# nrf9230_radiocore register map
Vendor: Nordic Semiconductor; Series: nRF92; File version: 1
CPU: CM33 r0p4, little endian, MPU, FPU, 3 interrupt priority bits, 480 interrupts, 8 SAU regions
Registers are 32-bit, read-write, reset 0x0 unless marked. A register's access mark holds for its fields unless they carry their own. Offsets are from the block's base; [hi:lo] are bit positions; {n}, {i} and the like mark numbered series; 'fields as' and 'values as' point back to an identical list.

## RTC_NS — Real-time counter 0
Base 0x4302B000
Same registers: RTC_S 0x5302B000
0x00 TASKS_START wo — Start RTC counter
  [0] TASKS_START
    1=Trigger task
0x04 TASKS_STOP wo — Stop RTC counter
  [0] TASKS_STOP
    1=Trigger task
0x08 TASKS_CLEAR wo — Clear RTC counter
  [0] TASKS_CLEAR
    1=Trigger task
0x0C TASKS_TRIGOVRFLW wo — Set counter to 0xFFFFF0
  [0] TASKS_TRIGOVRFLW
    1=Trigger task
{0x40+4i} TASKS_CAPTURE[{i}] (i=0..7) wo — Description collection: Capture RTC counter to CC[n] register
  [0] TASKS_CAPTURE — Capture RTC counter to CC[n] register
    1=Trigger task
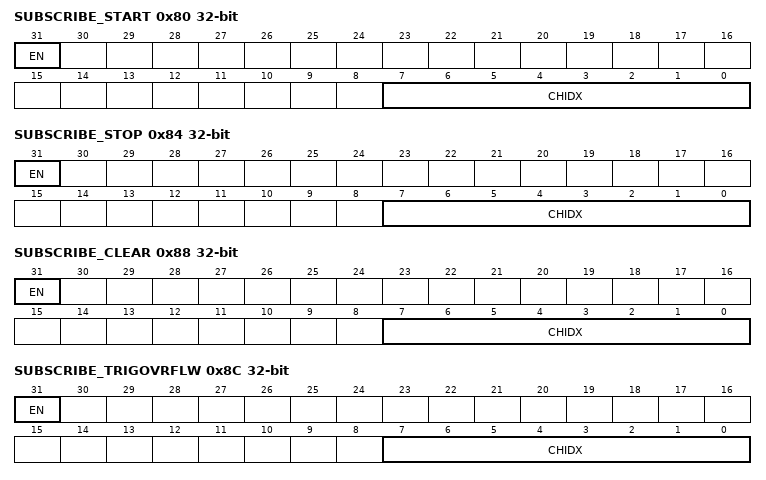
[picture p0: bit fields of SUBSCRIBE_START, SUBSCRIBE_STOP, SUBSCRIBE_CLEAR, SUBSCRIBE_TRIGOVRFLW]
0x80 SUBSCRIBE_START — Subscribe configuration for task START
  [31] EN
    0=Disabled (Disable subscription); 1=Enabled (Enable subscription)
  [7:0] CHIDX — DPPI channel that task START will subscribe to
0x84 SUBSCRIBE_STOP — Subscribe configuration for task STOP
  [31] EN
    values as SUBSCRIBE_START.EN
  [7:0] CHIDX — DPPI channel that task STOP will subscribe to
0x88 SUBSCRIBE_CLEAR — Subscribe configuration for task CLEAR
  [31] EN
    values as SUBSCRIBE_START.EN
  [7:0] CHIDX — DPPI channel that task CLEAR will subscribe to
0x8C SUBSCRIBE_TRIGOVRFLW — Subscribe configuration for task TRIGOVRFLW
  [31] EN
    values as SUBSCRIBE_START.EN
  [7:0] CHIDX — DPPI channel that task TRIGOVRFLW will subscribe to
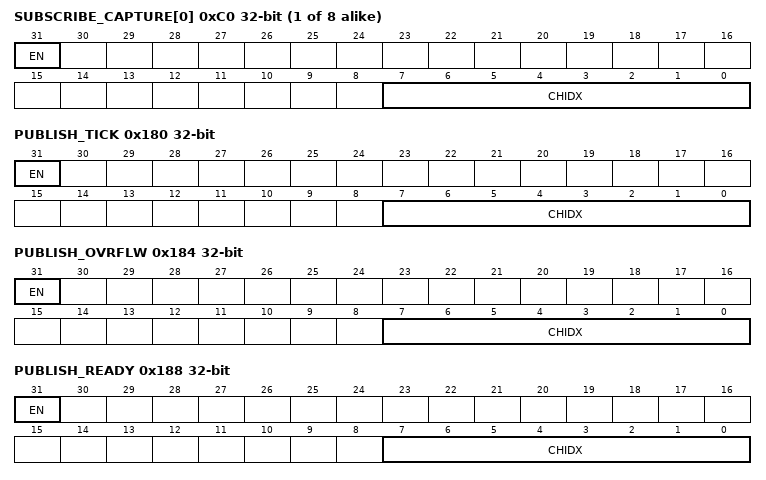
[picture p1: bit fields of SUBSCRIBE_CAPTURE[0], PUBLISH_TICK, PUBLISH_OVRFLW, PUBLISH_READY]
{0xC0+4i} SUBSCRIBE_CAPTURE[{i}] (i=0..7) — Description collection: Subscribe configuration for task CAPTURE[n]
  [31] EN
    values as SUBSCRIBE_START.EN
  [7:0] CHIDX — DPPI channel that task CAPTURE[n] will subscribe to
0x100 EVENTS_TICK — Event on counter increment
  [0] EVENTS_TICK
    0=NotGenerated (Event not generated); 1=Generated (Event generated)
0x104 EVENTS_OVRFLW — Event on counter overflow
  [0] EVENTS_OVRFLW
    values as EVENTS_TICK.EVENTS_TICK
0x108 EVENTS_READY — Event on LFCLK started
  [0] EVENTS_READY
    values as EVENTS_TICK.EVENTS_TICK
{0x140+4i} EVENTS_COMPARE[{i}] (i=0..7) — Description collection: Compare event on CC[n] match
  [0] EVENTS_COMPARE — Compare event on CC[n] match
    values as EVENTS_TICK.EVENTS_TICK
0x180 PUBLISH_TICK — Publish configuration for event TICK
  [31] EN
    0=Disabled (Disable publishing); 1=Enabled (Enable publishing)
  [7:0] CHIDX — DPPI channel that event TICK will publish to
0x184 PUBLISH_OVRFLW — Publish configuration for event OVRFLW
  [31] EN
    values as PUBLISH_TICK.EN
  [7:0] CHIDX — DPPI channel that event OVRFLW will publish to
0x188 PUBLISH_READY — Publish configuration for event READY
  [31] EN
    values as PUBLISH_TICK.EN
  [7:0] CHIDX — DPPI channel that event READY will publish to
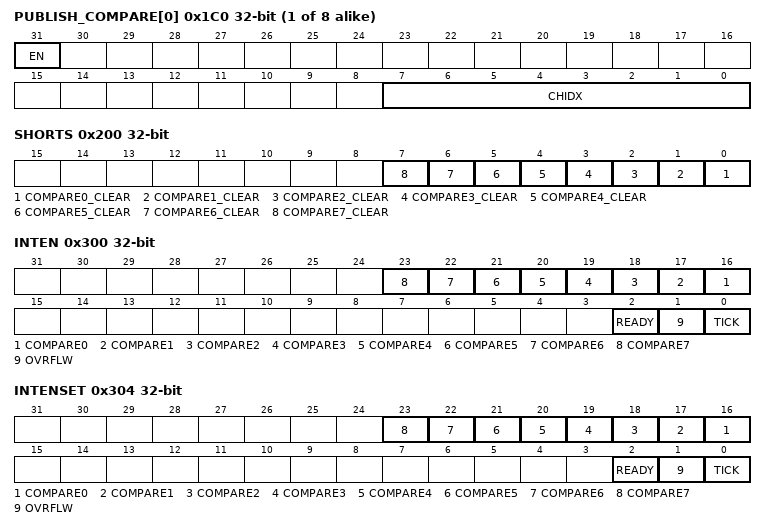
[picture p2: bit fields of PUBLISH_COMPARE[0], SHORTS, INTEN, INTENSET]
{0x1C0+4i} PUBLISH_COMPARE[{i}] (i=0..7) — Description collection: Publish configuration for event COMPARE[n]
  [31] EN
    values as PUBLISH_TICK.EN
  [7:0] CHIDX — DPPI channel that event COMPARE[n] will publish to
0x200 SHORTS — Shortcuts between local events and tasks
  [all] fields
    0=Disabled (Disable shortcut); 1=Enabled (Enable shortcut)
  [n] COMPARE{n}_CLEAR (n=0..7) — Shortcut between event COMPARE[{n}] and task CLEAR
0x300 INTEN — Enable or disable interrupt
  [all] fields
    0=Disabled; 1=Enabled
  [n+16] COMPARE{n} (n=0..7) — Enable or disable interrupt for event COMPARE[{n}]
  [2] READY — Enable or disable interrupt for event READY
  [1] OVRFLW — Enable or disable interrupt for event OVRFLW
  [0] TICK — Enable or disable interrupt for event TICK
0x304 INTENSET — Enable interrupt
  [all] fields
    on read: 0=Disabled (Read: Disabled); 1=Enabled (Read: Enabled) | on write: 1=Set (Enable)
  [n+16] COMPARE{n} (n=0..7) — Write '1' to enable interrupt for event COMPARE[{n}]
  [2] READY — Write '1' to enable interrupt for event READY
  [1] OVRFLW — Write '1' to enable interrupt for event OVRFLW
  [0] TICK — Write '1' to enable interrupt for event TICK
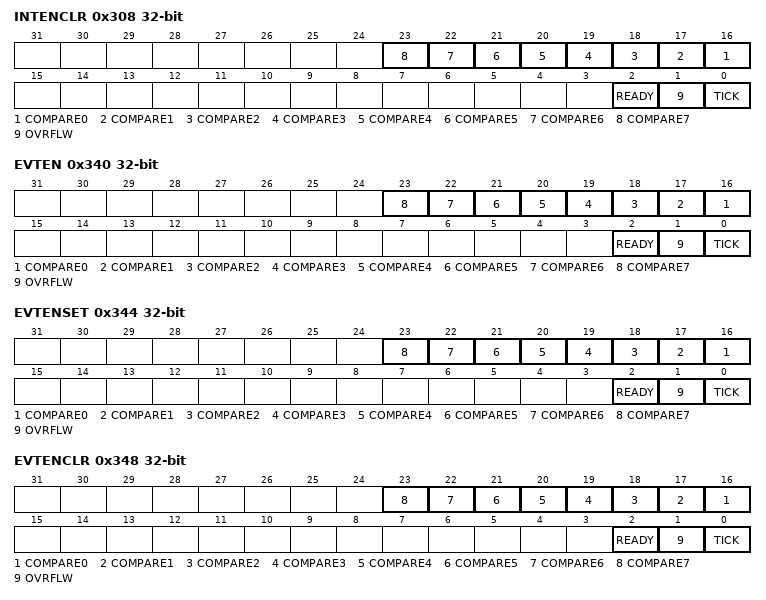
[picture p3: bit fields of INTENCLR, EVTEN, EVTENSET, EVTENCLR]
0x308 INTENCLR — Disable interrupt
  [all] fields
    on read: 0=Disabled (Read: Disabled); 1=Enabled (Read: Enabled) | on write: 1=Clear (Disable)
  [n+16] COMPARE{n} (n=0..7) — Write '1' to disable interrupt for event COMPARE[{n}]
  [2] READY — Write '1' to disable interrupt for event READY
  [1] OVRFLW — Write '1' to disable interrupt for event OVRFLW
  [0] TICK — Write '1' to disable interrupt for event TICK
0x340 EVTEN — Enable or disable event routing
  [all] fields
    0=Disabled; 1=Enabled
  [n+16] COMPARE{n} (n=0..7) — Enable or disable event routing for event COMPARE[{n}]
  [2] READY — Enable or disable event routing for event READY
  [1] OVRFLW — Enable or disable event routing for event OVRFLW
  [0] TICK — Enable or disable event routing for event TICK
0x344 EVTENSET — Enable event routing
  [all] fields
    values as the fields of INTENSET
  [n+16] COMPARE{n} (n=0..7) — Write '1' to enable event routing for event COMPARE[{n}]
  [2] READY — Write '1' to enable event routing for event READY
  [1] OVRFLW — Write '1' to enable event routing for event OVRFLW
  [0] TICK — Write '1' to enable event routing for event TICK
0x348 EVTENCLR — Disable event routing
  [all] fields
    values as the fields of INTENCLR
  [n+16] COMPARE{n} (n=0..7) — Write '1' to disable event routing for event COMPARE[{n}]
  [2] READY — Write '1' to disable event routing for event READY
  [1] OVRFLW — Write '1' to disable event routing for event OVRFLW
  [0] TICK — Write '1' to disable event routing for event TICK
0x400 STATUS ro — Counter status
  [0] COUNTER
    0=Stopped (Counter is stopped); 1=Started (Counter is started and LFCLK is available)
0x500 ENABLE — Clock enable
  [0] LFCLK — Request LFCLK
    0=Disable request LFCLK; 1=Enable request LFCLK
0x504 COUNTER ro — Current counter value
  [23:0] COUNTER — Counter value
0x508 PRESCALER — 12-bit prescaler for counter frequency (32768 / (PRESCALER + 1)). Must be written when RTC is stopped.
  [11:0] PRESCALER — Prescaler value
{0x540+4i} CC[{i}] (i=0..7) — Description collection: Compare register n
  [23:0] COMPARE — Compare value

## GLOBAL_RTC130_NS — Real-time counter 0
Base 0x4F928000
Same registers: GLOBAL_RTC131_NS 0x4F929000, GLOBAL_RTC130_S 0x5F928000, GLOBAL_RTC131_S 0x5F929000
Registers as RTC_NS; these are added or differ:
{0x540+4i} CC[{i}] (i=0..7) — Description collection: Compare register n
  [31:0] COMPARE — Compare value

## Notices in the file
Copyright (c) 2010 - 2024, Nordic Semiconductor ASA
All rights reserved.
Redistribution and use in source and binary forms, with or without modification,
are permitted provided that the following conditions are met:
1. Redistributions of source code must retain the above copyright notice, this
list of conditions and the following disclaimer.
2. Redistributions in binary form, except as embedded into a Nordic
Semiconductor ASA integrated circuit in a product or a software update for
such product, must reproduce the above copyright notice, this list of
conditions and the following disclaimer in the documentation and/or other
materials provided with the distribution.
3. Neither the name of Nordic Semiconductor ASA nor the names of its
contributors may be used to endorse or promote products derived from this
software without specific prior written permission.
4. This software, with or without modification, must only be used with a
Nordic Semiconductor ASA integrated circuit.
5. Any software provided in binary form under this license must not be reverse
engineered, decompiled, modified and/or disassembled.
THIS SOFTWARE IS PROVIDED BY NORDIC SEMICONDUCTOR ASA "AS IS" AND ANY EXPRESS
OR IMPLIED WARRANTIES, INCLUDING, BUT NOT LIMITED TO, THE IMPLIED WARRANTIES
OF MERCHANTABILITY, NONINFRINGEMENT, AND FITNESS FOR A PARTICULAR PURPOSE ARE
DISCLAIMED. IN NO EVENT SHALL NORDIC SEMICONDUCTOR ASA OR CONTRIBUTORS BE
LIABLE FOR ANY DIRECT, INDIRECT, INCIDENTAL, SPECIAL, EXEMPLARY, OR
CONSEQUENTIAL DAMAGES (INCLUDING, BUT NOT LIMITED TO, PROCUREMENT OF SUBSTITUTE
GOODS OR SERVICES; LOSS OF USE, DATA, OR PROFITS; OR BUSINESS INTERRUPTION)
HOWEVER CAUSED AND ON ANY THEORY OF LIABILITY, WHETHER IN CONTRACT, STRICT
LIABILITY, OR TORT (INCLUDING NEGLIGENCE OR OTHERWISE) ARISING IN ANY WAY OUT
OF THE USE OF THIS SOFTWARE, EVEN IF ADVISED OF THE POSSIBILITY OF SUCH DAMAGE.
